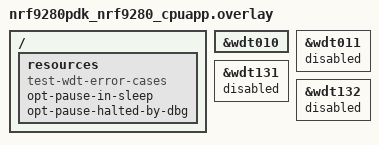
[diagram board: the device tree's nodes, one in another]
/*
 * Copyright (c) 2024 Nordic Semiconductor ASA
 *
 * SPDX-License-Identifier: Apache-2.0
 */

/ {
	resources {
		compatible = "test-wdt-error-cases";
		opt-pause-in-sleep;
		opt-pause-halted-by-dbg;
	};
};

&wdt010 {
	status = "okay";
};

&wdt011 {
	status = "disabled";
};

&wdt131 {
	status = "disabled";
};

&wdt132 {
	status = "disabled";
};
